VERSION ""

NS_ :

BS_:

BU_: DAQ HCU
VAL_TABLE_ Clutch_Status 2 "Closed" 1 "Open" 0 "Indeterminate" ;

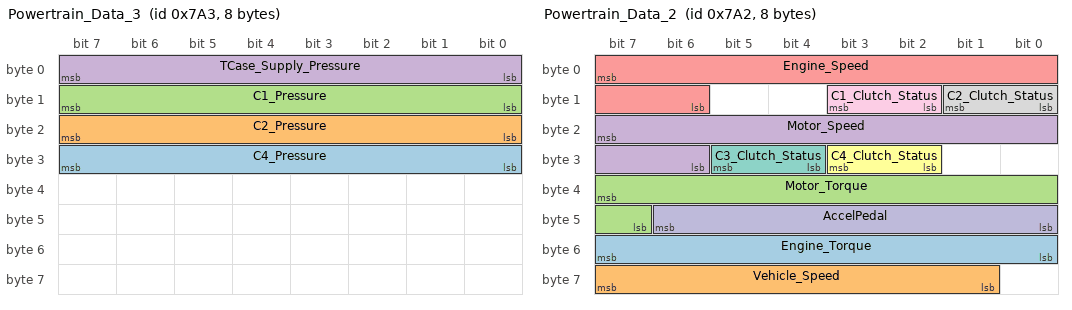
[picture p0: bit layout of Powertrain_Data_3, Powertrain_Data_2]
BO_ 1955 Powertrain_Data_3: 8 HCU
 SG_ C4_Pressure : 31|8@0+ (0.25,0) [0|63.75] "bar" Vector__XXX
 SG_ C2_Pressure : 23|8@0+ (0.25,0) [0|63.75] "bar" Vector__XXX
 SG_ C1_Pressure : 15|8@0+ (0.25,0) [0|63.75] "bar" Vector__XXX
 SG_ TCase_Supply_Pressure : 7|8@0+ (0.25,0) [0|63.75] "bar" Vector__XXX

BO_ 1954 Powertrain_Data_2: 8 HCU
 SG_ Engine_Torque : 55|8@0+ (2.5,-50) [-50|500] "N-m" Vector__XXX
 SG_ Vehicle_Speed : 63|7@0+ (1,-25) [-25|101] "MPH" Vector__XXX
 SG_ Motor_Torque : 39|9@0- (2.5,0) [-610|610] "N-m" Vector__XXX
 SG_ Motor_Speed : 23|10@0- (25,0) [-12700|12700] "RPM" Vector__XXX
 SG_ Engine_Speed : 7|10@0+ (10,0) [0|9000] "RPM" Vector__XXX
 SG_ C4_Clutch_Status : 27|2@0+ (1,0) [0|3] "enum" Vector__XXX
 SG_ C3_Clutch_Status : 29|2@0+ (1,0) [0|3] "enum" Vector__XXX
 SG_ C2_Clutch_Status : 9|2@0+ (1,0) [0|3] "enum" Vector__XXX
 SG_ C1_Clutch_Status : 11|2@0+ (1,0) [0|3] "enum" Vector__XXX
 SG_ AccelPedal : 46|7@0+ (1,0) [0|110] "%" Vector__XXX

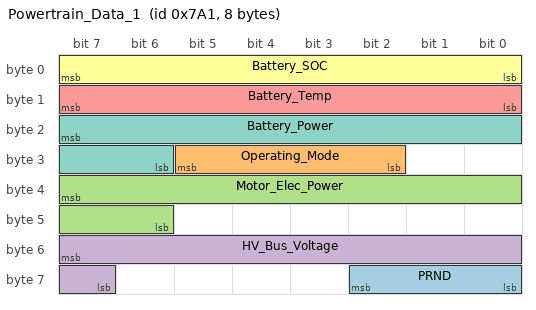
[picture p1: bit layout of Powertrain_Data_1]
BO_ 1953 Powertrain_Data_1: 8 HCU
 SG_ PRND : 58|3@0+ (1,0) [0|7] "enum" Vector__XXX
 SG_ Operating_Mode : 29|4@0+ (1,0) [0|15] "enum" Vector__XXX
 SG_ Motor_Elec_Power : 39|10@0- (0.5,0) [-250|250] "kWe" Vector__XXX
 SG_ HV_Bus_Voltage : 55|9@0+ (1,0) [0|505] "V" Vector__XXX
 SG_ Battery_Temp : 15|8@0+ (0.5,-40) [-40|87.5] "C" Vector__XXX
 SG_ Battery_SOC : 7|8@0+ (0.5,0) [0|110] "%" Vector__XXX
 SG_ Battery_Power : 23|10@0- (0.5,0) [-250|250] "kW" Vector__XXX

BA_DEF_ BO_  "GenMsgSendType" ENUM  "Cyclic","NotUsed","NotUsed","NotUsed","NotUsed","NotUsed","NotUsed","IfActive","NoMsgSendType","NotUsed";
BA_DEF_ BO_  "GenMsgCycleTime" INT 0 5000;
BA_DEF_  "BusType" STRING ;
BA_DEF_DEF_  "GenMsgSendType" "Cyclic";
BA_DEF_DEF_  "GenMsgCycleTime" 10;
BA_DEF_DEF_  "BusType" "CAN";
BA_ "GenMsgCycleTime" BO_ 1955 100;
BA_ "GenMsgCycleTime" BO_ 1954 100;
BA_ "GenMsgCycleTime" BO_ 1953 100;
VAL_ 1954 C4_Clutch_Status 2 "Closed" 1 "Open" 0 "Indeterminate" ;
VAL_ 1954 C3_Clutch_Status 2 "Closed" 1 "Open" 0 "Indeterminate" ;
VAL_ 1954 C2_Clutch_Status 2 "Closed" 1 "Open" 0 "Indeterminate" ;
VAL_ 1954 C1_Clutch_Status 2 "Closed" 1 "Open" 0 "Indeterminate" ;
VAL_ 1953 PRND 7 "Reserved" 6 "Reserved" 5 "LOW" 4 "DRIVE" 3 "REVERSE" 2 "PARK" 1 "NEUTRAL" 0 "Indeterminate" ;
VAL_ 1953 Operating_Mode 8 "Stationary Generator" 7 "2WD Hybrid Perfomance" 6 "4WD Hybrid Sustain" 5 "2WD Hybrid Sustain" 4 "4WD Electric" 3 "2WD Electric" 2 "4WD Conventional" 1 "2WD Conventional" 0 "Indeterminate" ;
